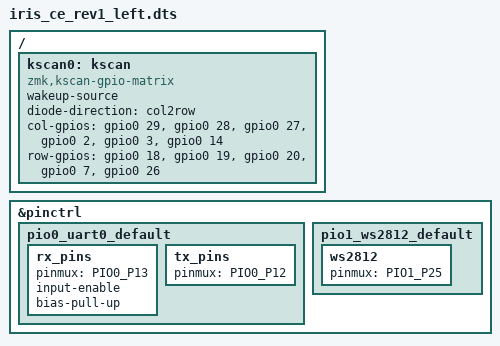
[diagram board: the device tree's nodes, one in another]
/*
 * Copyright (c) 2024 ZMK Contributors
 *
 * SPDX-License-Identifier: MIT
 */

/dts-v1/;
#include "iris_ce.dtsi"

/{
    kscan0: kscan {
        compatible = "zmk,kscan-gpio-matrix";
        wakeup-source;

        diode-direction = "col2row";
        col-gpios
            = <&gpio0 29 GPIO_ACTIVE_HIGH>
            , <&gpio0 28 GPIO_ACTIVE_HIGH>
            , <&gpio0 27 GPIO_ACTIVE_HIGH>
            , <&gpio0  2 GPIO_ACTIVE_HIGH>
            , <&gpio0  3 GPIO_ACTIVE_HIGH>
            , <&gpio0 14 GPIO_ACTIVE_HIGH>
            ;

        row-gpios
            = <&gpio0 18 (GPIO_ACTIVE_HIGH | GPIO_PULL_DOWN)>
            , <&gpio0 19 (GPIO_ACTIVE_HIGH | GPIO_PULL_DOWN)>
            , <&gpio0 20 (GPIO_ACTIVE_HIGH | GPIO_PULL_DOWN)>
            , <&gpio0  7 (GPIO_ACTIVE_HIGH | GPIO_PULL_DOWN)>
            , <&gpio0 26 (GPIO_ACTIVE_HIGH | GPIO_PULL_DOWN)>
            ;
    };
};

&pinctrl {
    pio0_uart0_default: pio0_uart0_default {
        rx_pins {
            pinmux = <PIO0_P13>;
            input-enable;
            bias-pull-up;
        };
        tx_pins {
            pinmux = <PIO0_P12>;
        };
    };
    
    pio1_ws2812_default: pio1_ws2812_default {
        ws2812 {
            pinmux = <PIO1_P25>;
        };
    };
};
